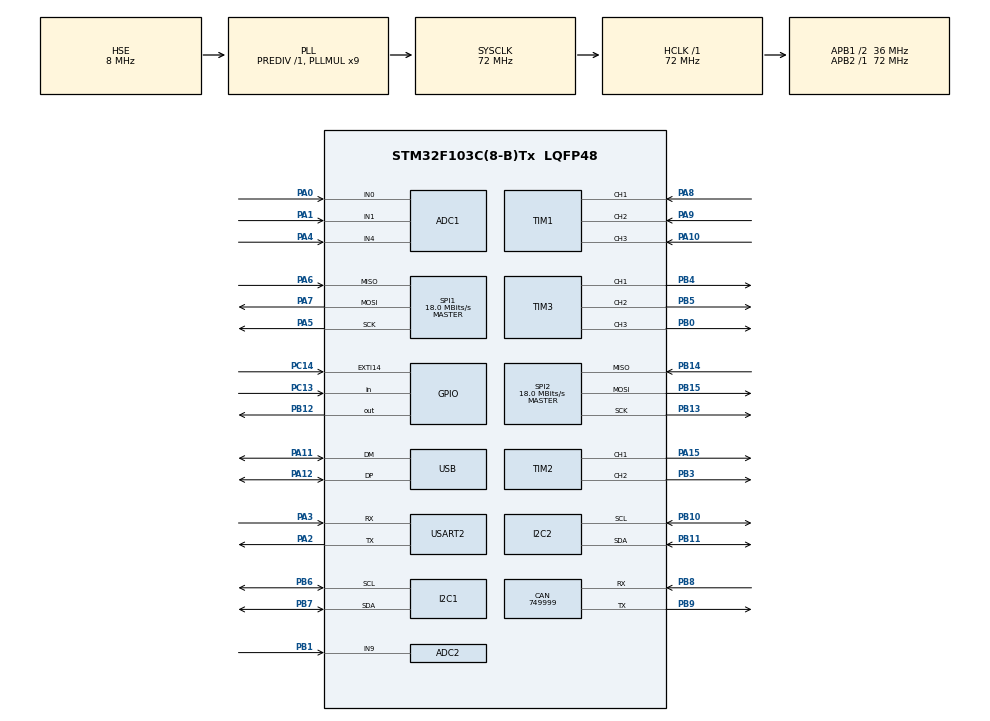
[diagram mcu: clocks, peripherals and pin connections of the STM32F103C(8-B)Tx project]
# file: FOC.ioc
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ADC1.Channel-0\#ChannelRegularConversion=ADC_CHANNEL_0
ADC1.NbrOfConversionFlag=1
ADC1.Rank-0\#ChannelRegularConversion=1
ADC1.SamplingTime-0\#ChannelRegularConversion=ADC_SAMPLETIME_1CYCLE_5
ADC1.master=1
ADC2.Channel-0\#ChannelRegularConversion=ADC_CHANNEL_9
ADC2.NbrOfConversionFlag=1
ADC2.Rank-0\#ChannelRegularConversion=1
ADC2.SamplingTime-0\#ChannelRegularConversion=ADC_SAMPLETIME_1CYCLE_5
CAN.BS1=CAN_BS1_1TQ
CAN.BS2=CAN_BS2_1TQ
CAN.CalculateBaudRate=749999
CAN.CalculateTimeBit=1333
CAN.CalculateTimeQuantum=444.44444444444446
Mcu.Family=STM32F1
Mcu.Name=STM32F103C(8-B)Tx
Mcu.Package=LQFP48
NVIC.PriorityGroup=NVIC_PRIORITYGROUP_4
NVIC.USB_LP_CAN1_RX0_IRQn=true\:0\:0\:false\:false\:true\:false\:true\:true
PA0-WKUP.Signal=ADCx_IN0
PA1.Signal=ADCx_IN1
PA10.Signal=S_TIM1_CH3
PA11.Mode=Device
PA11.Signal=USB_DM
PA12.Mode=Device
PA12.Signal=USB_DP
PA13.Mode=Serial_Wire
PA13.Signal=SYS_JTMS-SWDIO
PA14.Mode=Serial_Wire
PA14.Signal=SYS_JTCK-SWCLK
PA15.Signal=S_TIM2_CH1_ETR
PA2.Mode=Asynchronous
PA2.Signal=USART2_TX
PA3.Mode=Asynchronous
PA3.Signal=USART2_RX
PA4.Signal=ADCx_IN4
PA5.Mode=Full_Duplex_Master
PA5.Signal=SPI1_SCK
PA6.Mode=Full_Duplex_Master
PA6.Signal=SPI1_MISO
PA7.Mode=Full_Duplex_Master
PA7.Signal=SPI1_MOSI
PA8.Signal=S_TIM1_CH1
PA9.Signal=S_TIM1_CH2
PB0.Signal=S_TIM3_CH3
PB1.Signal=ADCx_IN9
PB10.Mode=I2C
PB10.Signal=I2C2_SCL
PB11.Mode=I2C
PB11.Signal=I2C2_SDA
PB12.Signal=GPIO_Output
PB13.Mode=Full_Duplex_Master
PB13.Signal=SPI2_SCK
PB14.Mode=Full_Duplex_Master
PB14.Signal=SPI2_MISO
PB15.Mode=Full_Duplex_Master
PB15.Signal=SPI2_MOSI
PB3.Signal=S_TIM2_CH2
PB4.Signal=S_TIM3_CH1
PB5.Signal=S_TIM3_CH2
PB6.Mode=I2C
PB6.Signal=I2C1_SCL
PB7.Mode=I2C
PB7.Signal=I2C1_SDA
PB8.Mode=CAN_Activate
PB8.Signal=CAN_RX
PB9.Mode=CAN_Activate
PB9.Signal=CAN_TX
PC13-TAMPER-RTC.Signal=GPIO_Input
PC14-OSC32_IN.Signal=GPXTI14
PD0-OSC_IN.Mode=HSE-External-Oscillator
PD0-OSC_IN.Signal=RCC_OSC_IN
PD1-OSC_OUT.Mode=HSE-External-Oscillator
PD1-OSC_OUT.Signal=RCC_OSC_OUT
ProjectManager.HeapSize=0x200
ProjectManager.StackSize=0x400
ProjectManager.TargetToolchain=CMake
RCC.ADCPresc=RCC_ADCPCLK2_DIV6
RCC.AHBFreq_Value=72000000
RCC.APB1CLKDivider=RCC_HCLK_DIV2
RCC.APB1Freq_Value=36000000
RCC.APB1TimFreq_Value=72000000
RCC.APB2Freq_Value=72000000
RCC.APB2TimFreq_Value=72000000
RCC.HCLKFreq_Value=72000000
RCC.PLLMUL=RCC_PLL_MUL9
RCC.SYSCLKFreq_VALUE=72000000
RCC.SYSCLKSource=RCC_SYSCLKSOURCE_PLLCLK
RCC.USBFreq_Value=48000000
RCC.USBPrescaler=RCC_USBCLKSOURCE_PLL_DIV1_5
SH.ADCx_IN0.0=ADC1_IN0,IN0
SH.ADCx_IN1.0=ADC1_IN1,IN1
SH.ADCx_IN4.0=ADC1_IN4,IN4
SH.ADCx_IN9.0=ADC2_IN9,IN9
SH.S_TIM1_CH1.0=TIM1_CH1,Encoder_Interface
SH.S_TIM1_CH2.0=TIM1_CH2,Encoder_Interface
SH.S_TIM1_CH3.0=TIM1_CH3,Input_Capture3_from_TI3
SH.S_TIM2_CH1_ETR.0=TIM2_CH1,PWM Generation1 CH1
SH.S_TIM2_CH2.0=TIM2_CH2,PWM Generation2 CH2
SH.S_TIM3_CH1.0=TIM3_CH1,PWM Generation1 CH1
SH.S_TIM3_CH2.0=TIM3_CH2,PWM Generation2 CH2
SH.S_TIM3_CH3.0=TIM3_CH3,PWM Generation3 CH3
SPI1.BaudRatePrescaler=SPI_BAUDRATEPRESCALER_4
SPI1.CalculateBaudRate=18.0 MBits/s
SPI1.Direction=SPI_DIRECTION_2LINES
SPI1.Mode=SPI_MODE_MASTER
SPI1.VirtualType=VM_MASTER
SPI2.BaudRatePrescaler=SPI_BAUDRATEPRESCALER_2
SPI2.CalculateBaudRate=18.0 MBits/s
SPI2.Direction=SPI_DIRECTION_2LINES
SPI2.Mode=SPI_MODE_MASTER
SPI2.VirtualType=VM_MASTER
TIM1.Channel-Input_Capture3_from_TI3=TIM_CHANNEL_3
TIM2.Channel-PWM\ Generation1\ CH1=TIM_CHANNEL_1
TIM2.Channel-PWM\ Generation2\ CH2=TIM_CHANNEL_2
TIM3.Channel-PWM\ Generation1\ CH1=TIM_CHANNEL_1
TIM3.Channel-PWM\ Generation2\ CH2=TIM_CHANNEL_2
TIM3.Channel-PWM\ Generation3\ CH3=TIM_CHANNEL_3
USART2.VirtualMode=VM_ASYNC
USB_DEVICE.CLASS_NAME_FS=DFU
USB_DEVICE.VirtualMode=Dfu
USB_DEVICE.VirtualModeFS=Dfu_FS
VP_USB_DEVICE_VS_USB_DEVICE_DFU_FS.Mode=DFU_FS
board=custom

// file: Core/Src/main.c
/* USER CODE BEGIN Header */
/**
  ******************************************************************************
  * @file           : main.c
  * @brief          : Main program body
  ******************************************************************************
  * @attention
  *
  * Copyright (c) 2026 STMicroelectronics.
  * All rights reserved.
  *
  * This software is licensed under terms that can be found in the LICENSE file
  * in the root directory of this software component.
  * If no LICENSE file comes with this software, it is provided AS-IS.
  *
  ******************************************************************************
  */
/* USER CODE END Header */
#include "main.h"
#include "adc.h"
#include "can.h"
#include "i2c.h"
#include "spi.h"
#include "tim.h"
#include "usart.h"
#include "usb_device.h"
#include "gpio.h"

/* USER CODE BEGIN Includes */
#include "app_motor.h"
#include "bsp_board.h"
#include "task_foc.h"
#include "task_manager.h"

/* USER CODE END Includes */

void SystemClock_Config(void);

int main(void)
{

  /* MCU Configuration--------------------------------------------------------*/

  /* Reset of all peripherals, Initializes the Flash interface and the Systick. */
  HAL_Init();

  /* Configure the system clock */
  SystemClock_Config();

  /* Initialize all configured peripherals */
  MX_GPIO_Init();
  MX_ADC1_Init();
  MX_ADC2_Init();
  MX_CAN_Init();
  MX_I2C1_Init();
  MX_I2C2_Init();
  MX_SPI1_Init();
  MX_SPI2_Init();
  MX_TIM1_Init();
  MX_TIM2_Init();
  MX_TIM3_Init();
  MX_USART2_UART_Init();
  MX_USB_DEVICE_Init();
  /* USER CODE BEGIN 2 */
  AppMotor_Init();
  BSP_Board_Init();
  TaskManager_Init();
  TaskFoc_Init();

  /* USER CODE END 2 */

  /* Infinite loop */
  while (1)
  {

    /* USER CODE BEGIN 3 */
     TaskManager_RunOnce();
  }
  /* USER CODE END 3 */
}

void SystemClock_Config(void)
{
  RCC_OscInitTypeDef RCC_OscInitStruct = {0};
  RCC_ClkInitTypeDef RCC_ClkInitStruct = {0};
  RCC_PeriphCLKInitTypeDef PeriphClkInit = {0};

  /** Initializes the RCC Oscillators according to the specified parameters
  * in the RCC_OscInitTypeDef structure.
  */
  RCC_OscInitStruct.OscillatorType = RCC_OSCILLATORTYPE_HSE;
  RCC_OscInitStruct.HSEState = RCC_HSE_ON;
  RCC_OscInitStruct.HSEPredivValue = RCC_HSE_PREDIV_DIV1;
  RCC_OscInitStruct.HSIState = RCC_HSI_ON;
  RCC_OscInitStruct.PLL.PLLState = RCC_PLL_ON;
  RCC_OscInitStruct.PLL.PLLSource = RCC_PLLSOURCE_HSE;
  RCC_OscInitStruct.PLL.PLLMUL = RCC_PLL_MUL9;
  if (HAL_RCC_OscConfig(&RCC_OscInitStruct) != HAL_OK)
  {
    Error_Handler();
  }

  /** Initializes the CPU, AHB and APB buses clocks
  */
  RCC_ClkInitStruct.ClockType = RCC_CLOCKTYPE_HCLK|RCC_CLOCKTYPE_SYSCLK
                              |RCC_CLOCKTYPE_PCLK1|RCC_CLOCKTYPE_PCLK2;
  RCC_ClkInitStruct.SYSCLKSource = RCC_SYSCLKSOURCE_PLLCLK;
  RCC_ClkInitStruct.AHBCLKDivider = RCC_SYSCLK_DIV1;
  RCC_ClkInitStruct.APB1CLKDivider = RCC_HCLK_DIV2;
  RCC_ClkInitStruct.APB2CLKDivider = RCC_HCLK_DIV1;

  if (HAL_RCC_ClockConfig(&RCC_ClkInitStruct, FLASH_LATENCY_2) != HAL_OK)
  {
    Error_Handler();
  }
  PeriphClkInit.PeriphClockSelection = RCC_PERIPHCLK_ADC|RCC_PERIPHCLK_USB;
  PeriphClkInit.AdcClockSelection = RCC_ADCPCLK2_DIV6;
  PeriphClkInit.UsbClockSelection = RCC_USBCLKSOURCE_PLL_DIV1_5;
  if (HAL_RCCEx_PeriphCLKConfig(&PeriphClkInit) != HAL_OK)
  {
    Error_Handler();
  }
}

void Error_Handler(void)
{
  __disable_irq();
  while (1)
  {
  }
}
